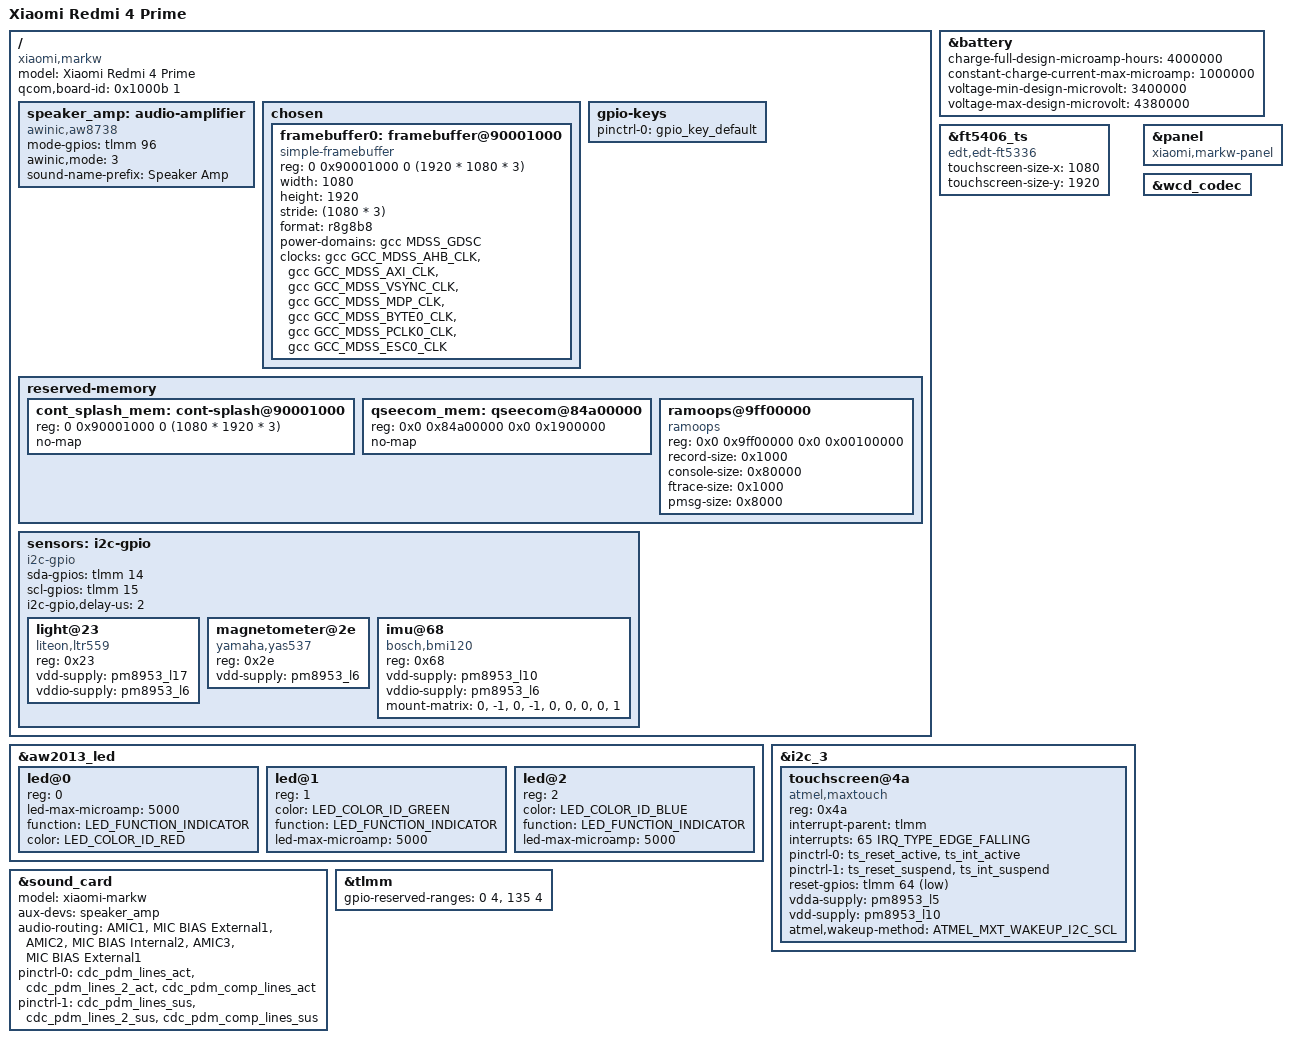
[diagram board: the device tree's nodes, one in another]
// SPDX-License-Identifier: BSD-3-Clause
/dts-v1/;

#include "msm8953-xiaomi-common.dtsi"
#include <dt-bindings/input/atmel-maxtouch.h>

/delete-node/ &qseecom_mem;

/ {
	model = "Xiaomi Redmi 4 Prime";
	compatible = "xiaomi,markw", "qcom,msm8953";
	qcom,board-id = <0x1000b 1>;

	speaker_amp: audio-amplifier {
		compatible = "awinic,aw8738";
		mode-gpios = <&tlmm 96 GPIO_ACTIVE_HIGH>;
		awinic,mode = <3>;
		sound-name-prefix = "Speaker Amp";
	};

	chosen {
		#address-cells = <2>;
		#size-cells = <2>;
		ranges;

		framebuffer0: framebuffer@90001000 {
			compatible = "simple-framebuffer";
			reg = <0 0x90001000 0 (1920 * 1080 * 3)>;

			width = <1080>;
			height = <1920>;
			stride = <(1080 * 3)>;
			format = "r8g8b8";

			power-domains = <&gcc MDSS_GDSC>;

			clocks = <&gcc GCC_MDSS_AHB_CLK>,
				 <&gcc GCC_MDSS_AXI_CLK>,
				 <&gcc GCC_MDSS_VSYNC_CLK>,
				 <&gcc GCC_MDSS_MDP_CLK>,
				 <&gcc GCC_MDSS_BYTE0_CLK>,
				 <&gcc GCC_MDSS_PCLK0_CLK>,
				 <&gcc GCC_MDSS_ESC0_CLK>;
		};
	};

	gpio-keys {
		pinctrl-0 = <&gpio_key_default>;
		pinctrl-names = "default";
	};

	reserved-memory {
		/delete-node/memory@85b00000;

		/delete-node/memory@90001000;
		cont_splash_mem: cont-splash@90001000 {
			reg = <0 0x90001000 0 (1080 * 1920 * 3)>;
			no-map;
		};

		/delete-node/memory@85b00000;
		qseecom_mem: qseecom@84a00000 {
			reg = <0x0 0x84a00000 0x0 0x1900000>;
			no-map;
		};

		ramoops@9ff00000 {
			compatible = "ramoops";
			reg = <0x0 0x9ff00000 0x0 0x00100000>;
			record-size = <0x1000>;
			console-size = <0x80000>;
			ftrace-size = <0x1000>;
			pmsg-size = <0x8000>;
		};
	};

	sensors: i2c-gpio {
		compatible = "i2c-gpio";
		sda-gpios = <&tlmm 14 (GPIO_ACTIVE_HIGH|GPIO_OPEN_DRAIN)>;
		scl-gpios = <&tlmm 15 (GPIO_ACTIVE_HIGH|GPIO_OPEN_DRAIN)>;
		i2c-gpio,delay-us = <2>;        /* ~100 kHz */
		#address-cells = <1>;
		#size-cells = <0>;

		light@23 {
			compatible = "liteon,ltr559";
			reg = <0x23>;

			vdd-supply = <&pm8953_l17>;
			vddio-supply = <&pm8953_l6>;
		};

		magnetometer@2e {
			compatible = "yamaha,yas537";
			reg = <0x2e>;

			vdd-supply = <&pm8953_l6>;
		};

		imu@68 {
			compatible = "bosch,bmi120";
			reg = <0x68>;

			vdd-supply = <&pm8953_l10>;
			vddio-supply = <&pm8953_l6>;

			mount-matrix = "0", "-1", "0",
					"-1", "0", "0",
					"0", "0", "1";
		};
	};
};

&aw2013_led {
	status = "okay";

	led@0 {
		reg = <0>;
		led-max-microamp = <5000>;
		function = LED_FUNCTION_INDICATOR;
		color = <LED_COLOR_ID_RED>;
	};

	led@1 {
		reg = <1>;
		color = <LED_COLOR_ID_GREEN>;
		function = LED_FUNCTION_INDICATOR;
		led-max-microamp = <5000>;
	};

	led@2 {
		reg = <2>;
		color = <LED_COLOR_ID_BLUE>;
		function = LED_FUNCTION_INDICATOR;
		led-max-microamp = <5000>;
	};
};

&battery {
	charge-full-design-microamp-hours = <4000000>;
	constant-charge-current-max-microamp = <1000000>;
	voltage-min-design-microvolt = <3400000>;
	voltage-max-design-microvolt = <4380000>;
};

&ft5406_ts {
	status = "okay";

	compatible = "edt,edt-ft5336", "edt,edt-ft5306";
	touchscreen-size-x = <1080>;
	touchscreen-size-y = <1920>;
};

&i2c_3 {
	status = "okay";

	touchscreen@4a {
		compatible = "atmel,maxtouch";
		reg = <0x4a>;

		interrupt-parent = <&tlmm>;
		interrupts = <65 IRQ_TYPE_EDGE_FALLING>;

		pinctrl-0 = <&ts_reset_active &ts_int_active>;
		pinctrl-1 = <&ts_reset_suspend &ts_int_suspend>;
		pinctrl-names = "default", "sleep";

		reset-gpios = <&tlmm 64 GPIO_ACTIVE_LOW>;

		vdda-supply = <&pm8953_l5>;
		vdd-supply = <&pm8953_l10>;

		atmel,wakeup-method = <ATMEL_MXT_WAKEUP_I2C_SCL>;
	};
};

&panel {
	compatible = "xiaomi,markw-panel";
};

&sound_card {
	model = "xiaomi-markw";

	aux-devs = <&speaker_amp>;
	audio-routing =
		"AMIC1", "MIC BIAS External1",
		"AMIC2", "MIC BIAS Internal2",
		"AMIC3", "MIC BIAS External1";

	pinctrl-0 = <&cdc_pdm_lines_act &cdc_pdm_lines_2_act &cdc_pdm_comp_lines_act>;
	pinctrl-1 = <&cdc_pdm_lines_sus &cdc_pdm_lines_2_sus &cdc_pdm_comp_lines_sus>;
	pinctrl-names = "default", "sleep";

	status = "okay";
};

&tlmm {
	gpio-reserved-ranges = <0 4>, <135 4>;
};

&wcd_codec {
	/delete-property/ qcom,gnd-jack-type-normally-open;
};
